# ATSAM3X8E register map
Vendor: Atmel; Series: SAM3X; File version: 0
CPU: CM3 r2p0, selectable endian, MPU, no FPU, 4 interrupt priority bits
Registers are 32-bit, read-write, reset 0x0 unless marked. A register's access mark holds for its fields unless they carry their own. Offsets are from the block's base; [hi:lo] are bit positions; {n}, {i} and the like mark numbered series.

## RSTC — Reset Controller
Base 0x400E1A00; register names take the prefix RSTC_
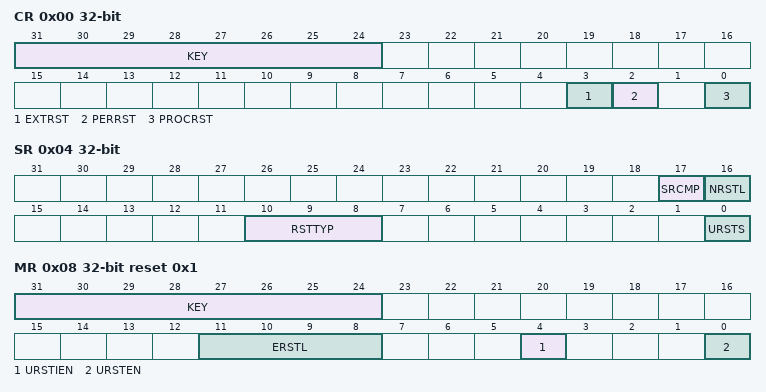
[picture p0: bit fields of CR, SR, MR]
0x00 CR wo reset not defined — Control Register
  [31:24] KEY — System Reset Key
    165=PASSWD (Writing any other value in this field aborts the write operation.)
  [3] EXTRST — External Reset
  [2] PERRST — Peripheral Reset
  [0] PROCRST — Processor Reset
0x04 SR ro — Status Register
  [17] SRCMP — Software Reset Command in Progress
  [16] NRSTL — NRST Pin Level
  [10:8] RSTTYP — Reset Type
    0=GeneralReset (First power-up Reset); 1=BackupReset (Return from Backup Mode); 2=WatchdogReset (Watchdog fault occurred); 3=SoftwareReset (Processor reset required by the software); 4=UserReset (NRST pin detected low)
  [0] URSTS — User Reset Status
0x08 MR reset 0x1 — Mode Register
  [31:24] KEY — Write Access Password
    165=PASSWD (Writing any other value in this field aborts the write operation.Always reads as 0.)
  [11:8] ERSTL — External Reset Length
  [4] URSTIEN — User Reset Interrupt Enable
  [0] URSTEN — User Reset Enable

## RTT — Real-time Timer
Base 0x400E1A30; register names take the prefix RTT_
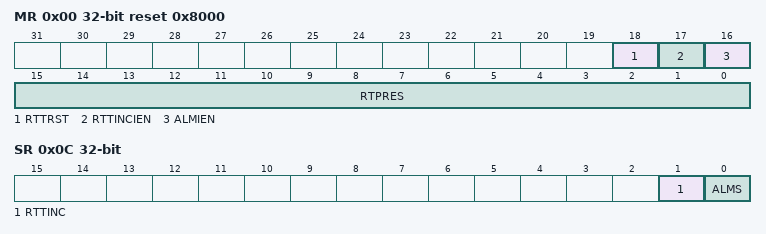
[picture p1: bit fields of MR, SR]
0x00 MR reset 0x8000 — Mode Register
  [18] RTTRST — Real-time Timer Restart
  [17] RTTINCIEN — Real-time Timer Increment Interrupt Enable
  [16] ALMIEN — Alarm Interrupt Enable
  [15:0] RTPRES — Real-time Timer Prescaler Value
0x04 AR reset 0xFFFFFFFF — Alarm Register
  [31:0] ALMV — Alarm Value
0x08 VR ro — Value Register
  [31:0] CRTV — Current Real-time Value
0x0C SR ro — Status Register
  [1] RTTINC — Real-time Timer Increment
  [0] ALMS — Real-time Alarm Status

## WDT — Watchdog Timer
Base 0x400E1A50; register names take the prefix WDT_
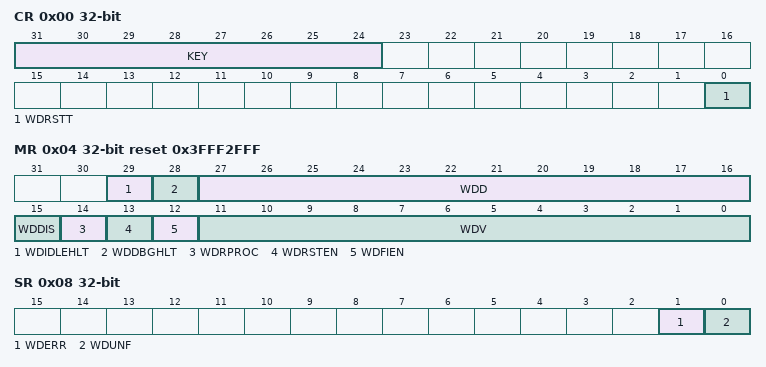
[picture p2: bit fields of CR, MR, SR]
0x00 CR wo reset not defined — Control Register
  [31:24] KEY — Password.
    165=PASSWD (Writing any other value in this field aborts the write operation.)
  [0] WDRSTT — Watchdog Restart
0x04 MR reset 0x3FFF2FFF — Mode Register
  [29] WDIDLEHLT — Watchdog Idle Halt
  [28] WDDBGHLT — Watchdog Debug Halt
  [27:16] WDD — Watchdog Delta Value
  [15] WDDIS — Watchdog Disable
  [14] WDRPROC — Watchdog Reset Processor
  [13] WDRSTEN — Watchdog Reset Enable
  [12] WDFIEN — Watchdog Fault Interrupt Enable
  [11:0] WDV — Watchdog Counter Value
0x08 SR ro — Status Register
  [1] WDERR — Watchdog Error
  [0] WDUNF — Watchdog Underflow

## GPBR — General Purpose Backup Registers
Base 0x400E1A90; register names take the prefix GPBR_
{0x0+4i} GPBR[{i}] (i=0..7) reset not defined — General Purpose Backup Register
  [31:0] GPBR_VALUE — Value of GPBR x

## SYST — System timer, SysTick
Base 0xE000E010; register names take the prefix SYST_
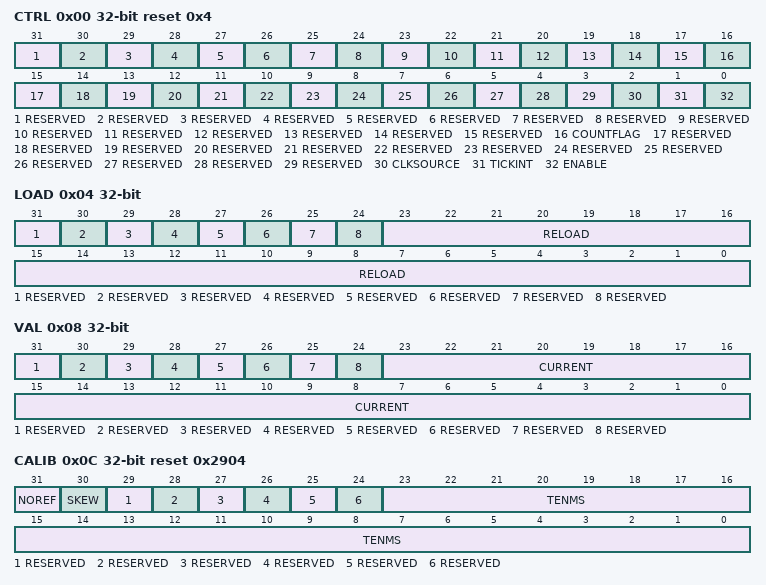
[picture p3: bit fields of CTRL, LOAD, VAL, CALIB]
0x00 CTRL access per field reset 0x4 — SysTick Control and Status Register
  [31] RESERVED ro
  [30] RESERVED ro
  [29] RESERVED ro
  [28] RESERVED ro
  [27] RESERVED ro
  [26] RESERVED ro
  [25] RESERVED ro
  [24] RESERVED ro
  [23] RESERVED ro
  [22] RESERVED ro
  [21] RESERVED ro
  [20] RESERVED ro
  [19] RESERVED ro
  [18] RESERVED ro
  [17] RESERVED ro
  [16] COUNTFLAG rw
  [15] RESERVED ro
  [14] RESERVED ro
  [13] RESERVED ro
  [12] RESERVED ro
  [11] RESERVED ro
  [10] RESERVED ro
  [9] RESERVED ro
  [8] RESERVED ro
  [7] RESERVED ro
  [6] RESERVED ro
  [5] RESERVED ro
  [4] RESERVED ro
  [3] RESERVED ro
  [2] CLKSOURCE rw
    0=MCK_8; 1=MCK
  [1] TICKINT rw
  [0] ENABLE rw
0x04 LOAD access per field — SysTick Reload Value Register
  [31] RESERVED ro
  [30] RESERVED ro
  [29] RESERVED ro
  [28] RESERVED ro
  [27] RESERVED ro
  [26] RESERVED ro
  [25] RESERVED ro
  [24] RESERVED ro
  [23:0] RELOAD rw — Value to load into the SysTick Current Value Register when the counter reaches 0
0x08 VAL access per field — SysTick Current Value Register
  [31] RESERVED ro
  [30] RESERVED ro
  [29] RESERVED ro
  [28] RESERVED ro
  [27] RESERVED ro
  [26] RESERVED ro
  [25] RESERVED ro
  [24] RESERVED ro
  [23:0] CURRENT rw — Current value at the time the register is accessed
0x0C CALIB ro reset 0x2904 — SysTick Calibration Value Register
  [31] NOREF
    0=The reference clock is provided; 1=The reference clock is not provided
  [30] SKEW
    0=10ms calibration value is exact; 1=10ms calibration value is inexact, because of the clock frequency
  [29] RESERVED
  [28] RESERVED
  [27] RESERVED
  [26] RESERVED
  [25] RESERVED
  [24] RESERVED
  [23:0] TENMS — Reload value to use for 10ms timing

## NVIC — Nested Vectored Interrupt Controller
Base 0xE000E000
0x100 ISER0 — Interrupt Set-Enable Register
  [31:0] SETENA
0x104 ISER1 — Interrupt Set-Enable Register
  [31:0] SETENA
0x180 ICER0 — Interrupt Clear-Enable Register
  [31:0] CLRENA
0x184 ICER1 — Interrupt Clear-Enable Register
  [31:0] CLRENA
0x200 ISPR0 — Interrupt Set-Pending Register
  [31:0] SETPEND
0x204 ISPR1 — Interrupt Set-Pending Register
  [31:0] SETPEND
0x280 ICPR0 — Interrupt Clear-Pending Register
  [31:0] CLRPEND
0x284 ICPR1 — Interrupt Clear-Pending Register
  [31:0] CLRPEND
0x300 IABR0 ro — Interrupt Active Bit Register
  [31:0] ACTIVE
0x304 IABR1 ro — Interrupt Active Bit Register
  [31:0] ACTIVE
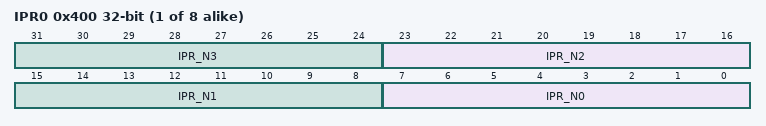
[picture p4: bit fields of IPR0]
{0x400+4i} IPR{i} (i=0..7) — Interrupt Priority Register
  [8n+7:8n] IPR_N{n} (n=0..3)
0xF00 STIR wo — Software Triggered Interrupt Register
  [8:0] INTID — interrupt to be triggered
